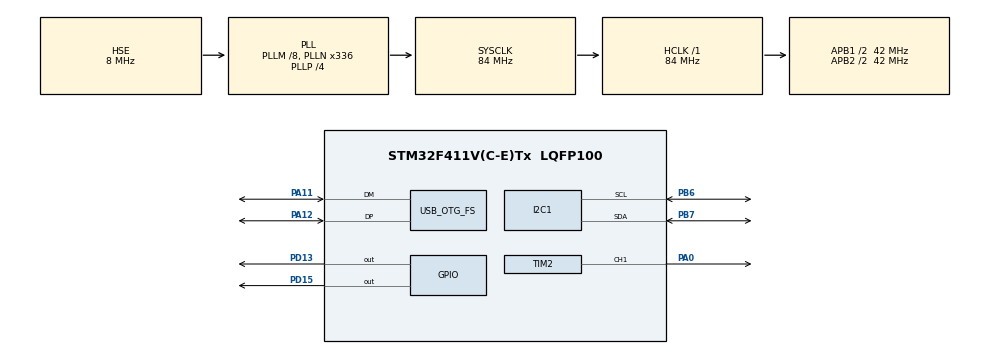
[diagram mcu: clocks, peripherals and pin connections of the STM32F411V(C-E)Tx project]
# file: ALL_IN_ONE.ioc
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Mcu.Family=STM32F4
Mcu.Name=STM32F411V(C-E)Tx
Mcu.Package=LQFP100
NVIC.OTG_FS_IRQn=true\:0\:0\:false\:false\:true\:true\:true\:true
NVIC.PriorityGroup=NVIC_PRIORITYGROUP_4
PA0-WKUP.Signal=S_TIM2_CH1_ETR
PA11.Mode=Device_Only
PA11.Signal=USB_OTG_FS_DM
PA12.Mode=Device_Only
PA12.Signal=USB_OTG_FS_DP
PA13.Mode=Serial_Wire
PA13.Signal=SYS_JTMS-SWDIO
PA14.Mode=Serial_Wire
PA14.Signal=SYS_JTCK-SWCLK
PB6.Mode=I2C
PB6.Signal=I2C1_SCL
PB7.Mode=I2C
PB7.Signal=I2C1_SDA
PD13.GPIO_Speed=GPIO_SPEED_FREQ_HIGH
PD13.Signal=GPIO_Output
PD15.GPIO_Speed=GPIO_SPEED_FREQ_HIGH
PD15.Signal=GPIO_Output
PH0\ -\ OSC_IN.Mode=HSE-External-Oscillator
PH0\ -\ OSC_IN.Signal=RCC_OSC_IN
PH1\ -\ OSC_OUT.Mode=HSE-External-Oscillator
PH1\ -\ OSC_OUT.Signal=RCC_OSC_OUT
ProjectManager.HeapSize=0x200
ProjectManager.StackSize=0x400
ProjectManager.TargetToolchain=STM32CubeIDE
RCC.48MHZClocksFreq_Value=48000000
RCC.AHBFreq_Value=84000000
RCC.APB1CLKDivider=RCC_HCLK_DIV2
RCC.APB1Freq_Value=42000000
RCC.APB1TimFreq_Value=84000000
RCC.APB2CLKDivider=RCC_HCLK_DIV2
RCC.APB2Freq_Value=42000000
RCC.APB2TimFreq_Value=84000000
RCC.CortexFreq_Value=84000000
RCC.HCLKFreq_Value=84000000
RCC.HSE_VALUE=8000000
RCC.HSI_VALUE=16000000
RCC.LSE_VALUE=32768
RCC.PLLM=8
RCC.PLLN=336
RCC.PLLP=RCC_PLLP_DIV4
RCC.PLLQ=7
RCC.SYSCLKFreq_VALUE=84000000
RCC.SYSCLKSource=RCC_SYSCLKSOURCE_PLLCLK
RCC.VCOOutputFreq_Value=336000000
SH.S_TIM2_CH1_ETR.0=TIM2_CH1,PWM Generation1 CH1
TIM2.Channel-PWM\ Generation1\ CH1=TIM_CHANNEL_1
TIM2.Period=1000-1
TIM2.Prescaler=1680-1
USB_DEVICE.CLASS_NAME_FS=CDC
USB_DEVICE.VirtualMode=Cdc
USB_DEVICE.VirtualModeFS=Cdc_FS
USB_OTG_FS.VirtualMode=Device_Only
VP_TIM2_VS_ClockSourceINT.Mode=Internal
VP_USB_DEVICE_VS_USB_DEVICE_CDC_FS.Mode=CDC_FS
board=custom

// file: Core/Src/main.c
/* USER CODE BEGIN Header */
/**
  ******************************************************************************
  * @file           : main.c
  * @brief          : Main program body
  ******************************************************************************
  * @attention
  *
  * Copyright (c) 2023 STMicroelectronics.
  * All rights reserved.
  *
  * This software is licensed under terms that can be found in the LICENSE file
  * in the root directory of this software component.
  * If no LICENSE file comes with this software, it is provided AS-IS.
  *
  ******************************************************************************
  */
/* USER CODE END Header */
#include "main.h"
#include "usb_device.h"

/* USER CODE BEGIN Includes */
#include "i2c-lcd.h"
#include "stdio.h"
/* USER CODE END Includes */

/* USER CODE BEGIN PTD */

uint8_t receive_data[64];

uint8_t mystring0[] = "Error";
uint8_t mystring1[] = "Welcome";

/* USER CODE END PTD */

I2C_HandleTypeDef hi2c1;

TIM_HandleTypeDef htim2;

void SystemClock_Config(void);
static void MX_GPIO_Init(void);
static void MX_I2C1_Init(void);
static void MX_TIM2_Init(void);

int main(void)
{

  /* MCU Configuration--------------------------------------------------------*/

  /* Reset of all peripherals, Initializes the Flash interface and the Systick. */
  HAL_Init();

  /* Configure the system clock */
  SystemClock_Config();

  /* Initialize all configured peripherals */
  MX_GPIO_Init();
  MX_I2C1_Init();
  MX_TIM2_Init();
  MX_USB_DEVICE_Init();
  /* USER CODE BEGIN 2 */

  HAL_TIM_PWM_Start(&htim2, TIM_CHANNEL_1);

  lcd_init();
  lcd_put_cur(0, 0);
  lcd_send_string("LET 'S");
  lcd_put_cur(1, 0);
  lcd_send_string("BEGIN");

  int i, j;
  /* USER CODE END 2 */

  /* Infinite loop */
  while (1)
  {

	  	  	  // USB_OTG_FS

	  i = strcmp(mystring0, receive_data);				// Intruder ALert!
	  if (i == 0)
	  {
		  HAL_GPIO_WritePin(GPIOD, GPIO_PIN_13, 1);
		  HAL_GPIO_WritePin(GPIOD, GPIO_PIN_15, 0);

		  HAL_Delay(4000);

		  htim2.Instance->CCR1 = 15;					// Micro_Servo

		  lcd_clear();
		  lcd_put_cur(0, 3);							// I2C_LCD
		  lcd_send_string("DOOR LOCKED");
		  lcd_put_cur(1, 0);
		  lcd_send_string(" CANNOT GET IN!");
		  HAL_Delay(1000);
	  }

	  j = strcmp(mystring1, receive_data);
	  if (j == 0)
	  {

		  HAL_GPIO_WritePin(GPIOD, GPIO_PIN_13, 0);
		  HAL_GPIO_WritePin(GPIOD, GPIO_PIN_15, 1);

		  htim2.Instance->CCR1 = 125;

		  lcd_clear();
		  lcd_put_cur(0, 5);
		  lcd_send_string("WELCOME");
		  lcd_put_cur(1, 0);
		  lcd_send_string("  DOOR OPENED");

		  HAL_Delay(4000);

		  htim2.Instance->CCR1 = 15;					// Micro_Servo

		  lcd_clear();
		  		  lcd_put_cur(0, 3);							// I2C_LCD
		  		  lcd_send_string("DOOR LOCKED");
		  		  lcd_put_cur(1, 0);
		  		  lcd_send_string(" CANNOT GET IN!");
		  HAL_Delay(1000);

	  }

  }
}

void SystemClock_Config(void)
{
  RCC_OscInitTypeDef RCC_OscInitStruct = {0};
  RCC_ClkInitTypeDef RCC_ClkInitStruct = {0};

  /** Configure the main internal regulator output voltage
  */
  __HAL_RCC_PWR_CLK_ENABLE();
  __HAL_PWR_VOLTAGESCALING_CONFIG(PWR_REGULATOR_VOLTAGE_SCALE1);

  /** Initializes the RCC Oscillators according to the specified parameters
  * in the RCC_OscInitTypeDef structure.
  */
  RCC_OscInitStruct.OscillatorType = RCC_OSCILLATORTYPE_HSE;
  RCC_OscInitStruct.HSEState = RCC_HSE_ON;
  RCC_OscInitStruct.PLL.PLLState = RCC_PLL_ON;
  RCC_OscInitStruct.PLL.PLLSource = RCC_PLLSOURCE_HSE;
  RCC_OscInitStruct.PLL.PLLM = 8;
  RCC_OscInitStruct.PLL.PLLN = 336;
  RCC_OscInitStruct.PLL.PLLP = RCC_PLLP_DIV4;
  RCC_OscInitStruct.PLL.PLLQ = 7;
  if (HAL_RCC_OscConfig(&RCC_OscInitStruct) != HAL_OK)
  {
    Error_Handler();
  }

  /** Initializes the CPU, AHB and APB buses clocks
  */
  RCC_ClkInitStruct.ClockType = RCC_CLOCKTYPE_HCLK|RCC_CLOCKTYPE_SYSCLK
                              |RCC_CLOCKTYPE_PCLK1|RCC_CLOCKTYPE_PCLK2;
  RCC_ClkInitStruct.SYSCLKSource = RCC_SYSCLKSOURCE_PLLCLK;
  RCC_ClkInitStruct.AHBCLKDivider = RCC_SYSCLK_DIV1;
  RCC_ClkInitStruct.APB1CLKDivider = RCC_HCLK_DIV2;
  RCC_ClkInitStruct.APB2CLKDivider = RCC_HCLK_DIV2;

  if (HAL_RCC_ClockConfig(&RCC_ClkInitStruct, FLASH_LATENCY_2) != HAL_OK)
  {
    Error_Handler();
  }
}

static void MX_I2C1_Init(void)
{

  hi2c1.Instance = I2C1;
  hi2c1.Init.ClockSpeed = 100000;
  hi2c1.Init.DutyCycle = I2C_DUTYCYCLE_2;
  hi2c1.Init.OwnAddress1 = 0;
  hi2c1.Init.AddressingMode = I2C_ADDRESSINGMODE_7BIT;
  hi2c1.Init.DualAddressMode = I2C_DUALADDRESS_DISABLE;
  hi2c1.Init.OwnAddress2 = 0;
  hi2c1.Init.GeneralCallMode = I2C_GENERALCALL_DISABLE;
  hi2c1.Init.NoStretchMode = I2C_NOSTRETCH_DISABLE;
  if (HAL_I2C_Init(&hi2c1) != HAL_OK)
  {
    Error_Handler();
  }

}

static void MX_TIM2_Init(void)
{

  TIM_ClockConfigTypeDef sClockSourceConfig = {0};
  TIM_MasterConfigTypeDef sMasterConfig = {0};
  TIM_OC_InitTypeDef sConfigOC = {0};

  htim2.Instance = TIM2;
  htim2.Init.Prescaler = 1680-1;
  htim2.Init.CounterMode = TIM_COUNTERMODE_UP;
  htim2.Init.Period = 1000-1;
  htim2.Init.ClockDivision = TIM_CLOCKDIVISION_DIV1;
  htim2.Init.AutoReloadPreload = TIM_AUTORELOAD_PRELOAD_DISABLE;
  if (HAL_TIM_Base_Init(&htim2) != HAL_OK)
  {
    Error_Handler();
  }
  sClockSourceConfig.ClockSource = TIM_CLOCKSOURCE_INTERNAL;
  if (HAL_TIM_ConfigClockSource(&htim2, &sClockSourceConfig) != HAL_OK)
  {
    Error_Handler();
  }
  if (HAL_TIM_PWM_Init(&htim2) != HAL_OK)
  {
    Error_Handler();
  }
  sMasterConfig.MasterOutputTrigger = TIM_TRGO_RESET;
  sMasterConfig.MasterSlaveMode = TIM_MASTERSLAVEMODE_DISABLE;
  if (HAL_TIMEx_MasterConfigSynchronization(&htim2, &sMasterConfig) != HAL_OK)
  {
    Error_Handler();
  }
  sConfigOC.OCMode = TIM_OCMODE_PWM1;
  sConfigOC.Pulse = 0;
  sConfigOC.OCPolarity = TIM_OCPOLARITY_HIGH;
  sConfigOC.OCFastMode = TIM_OCFAST_DISABLE;
  if (HAL_TIM_PWM_ConfigChannel(&htim2, &sConfigOC, TIM_CHANNEL_1) != HAL_OK)
  {
    Error_Handler();
  }
  HAL_TIM_MspPostInit(&htim2);

}

static void MX_GPIO_Init(void)
{
  GPIO_InitTypeDef GPIO_InitStruct = {0};

  /* GPIO Ports Clock Enable */
  __HAL_RCC_GPIOH_CLK_ENABLE();
  __HAL_RCC_GPIOA_CLK_ENABLE();
  __HAL_RCC_GPIOD_CLK_ENABLE();
  __HAL_RCC_GPIOB_CLK_ENABLE();

  /*Configure GPIO pin Output Level */
  HAL_GPIO_WritePin(GPIOD, GPIO_PIN_13|GPIO_PIN_15, GPIO_PIN_RESET);

  /*Configure GPIO pins : PD13 PD15 */
  GPIO_InitStruct.Pin = GPIO_PIN_13|GPIO_PIN_15;
  GPIO_InitStruct.Mode = GPIO_MODE_OUTPUT_PP;
  GPIO_InitStruct.Pull = GPIO_NOPULL;
  GPIO_InitStruct.Speed = GPIO_SPEED_FREQ_HIGH;
  HAL_GPIO_Init(GPIOD, &GPIO_InitStruct);

}

void Error_Handler(void)
{
  __disable_irq();
  while (1)
  {
  }
}
